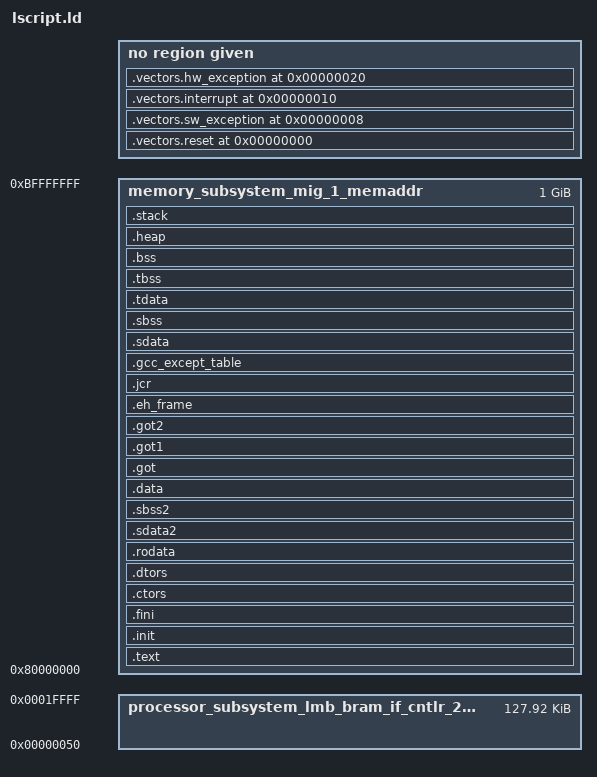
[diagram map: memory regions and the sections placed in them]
/*******************************************************************/
/*                                                                 */
/* This file is automatically generated by linker script generator.*/
/*                                                                 */
/* Version:                                 */
/*                                                                 */
/* Copyright (c) 2010-2016 Xilinx, Inc.  All rights reserved.      */
/*                                                                 */
/* Description : MicroBlaze Linker Script                          */
/*                                                                 */
/*******************************************************************/

_STACK_SIZE = DEFINED(_STACK_SIZE) ? _STACK_SIZE : 0x4000;
_HEAP_SIZE = DEFINED(_HEAP_SIZE) ? _HEAP_SIZE : 0x8000;

/* Define Memories in the system */

MEMORY
{
   processor_subsystem_lmb_bram_if_cntlr_2_Mem_processor_subsystem_lmb_bram_if_cntlr_1_Mem : ORIGIN = 0x50, LENGTH = 0x1FFB0
   memory_subsystem_mig_1_memaddr : ORIGIN = 0x80000000, LENGTH = 0x40000000
}

/* Specify the default entry point to the program */

ENTRY(_start)

/* Define the sections, and where they are mapped in memory */

SECTIONS
{
.vectors.reset 0x0 : {
   KEEP (*(.vectors.reset))
}

.vectors.sw_exception 0x8 : {
   KEEP (*(.vectors.sw_exception))
}

.vectors.interrupt 0x10 : {
   KEEP (*(.vectors.interrupt))
}

.vectors.hw_exception 0x20 : {
   KEEP (*(.vectors.hw_exception))
}

.text : {
   *(.text)
   *(.text.*)
   *(.gnu.linkonce.t.*)
} > memory_subsystem_mig_1_memaddr

.init : {
   KEEP (*(.init))
} > memory_subsystem_mig_1_memaddr

.fini : {
   KEEP (*(.fini))
} > memory_subsystem_mig_1_memaddr

.ctors : {
   __CTOR_LIST__ = .;
   ___CTORS_LIST___ = .;
   KEEP (*crtbegin.o(.ctors))
   KEEP (*(EXCLUDE_FILE(*crtend.o) .ctors))
   KEEP (*(SORT(.ctors.*)))
   KEEP (*(.ctors))
   __CTOR_END__ = .;
   ___CTORS_END___ = .;
} > memory_subsystem_mig_1_memaddr

.dtors : {
   __DTOR_LIST__ = .;
   ___DTORS_LIST___ = .;
   KEEP (*crtbegin.o(.dtors))
   KEEP (*(EXCLUDE_FILE(*crtend.o) .dtors))
   KEEP (*(SORT(.dtors.*)))
   KEEP (*(.dtors))
   PROVIDE(__DTOR_END__ = .);
   PROVIDE(___DTORS_END___ = .);
} > memory_subsystem_mig_1_memaddr

.rodata : {
   __rodata_start = .;
   *(.rodata)
   *(.rodata.*)
   *(.gnu.linkonce.r.*)
   __rodata_end = .;
} > memory_subsystem_mig_1_memaddr

.sdata2 : {
   . = ALIGN(8);
   __sdata2_start = .;
   *(.sdata2)
   *(.sdata2.*)
   *(.gnu.linkonce.s2.*)
   . = ALIGN(8);
   __sdata2_end = .;
} > memory_subsystem_mig_1_memaddr

.sbss2 : {
   __sbss2_start = .;
   *(.sbss2)
   *(.sbss2.*)
   *(.gnu.linkonce.sb2.*)
   __sbss2_end = .;
} > memory_subsystem_mig_1_memaddr

.data : {
   . = ALIGN(4);
   __data_start = .;
   *(.data)
   *(.data.*)
   *(.gnu.linkonce.d.*)
   __data_end = .;
} > memory_subsystem_mig_1_memaddr

.got : {
   *(.got)
} > memory_subsystem_mig_1_memaddr

.got1 : {
   *(.got1)
} > memory_subsystem_mig_1_memaddr

.got2 : {
   *(.got2)
} > memory_subsystem_mig_1_memaddr

.eh_frame : {
   *(.eh_frame)
} > memory_subsystem_mig_1_memaddr

.jcr : {
   *(.jcr)
} > memory_subsystem_mig_1_memaddr

.gcc_except_table : {
   *(.gcc_except_table)
} > memory_subsystem_mig_1_memaddr

.sdata : {
   . = ALIGN(8);
   __sdata_start = .;
   *(.sdata)
   *(.sdata.*)
   *(.gnu.linkonce.s.*)
   __sdata_end = .;
} > memory_subsystem_mig_1_memaddr

.sbss (NOLOAD) : {
   . = ALIGN(4);
   __sbss_start = .;
   *(.sbss)
   *(.sbss.*)
   *(.gnu.linkonce.sb.*)
   . = ALIGN(8);
   __sbss_end = .;
} > memory_subsystem_mig_1_memaddr

.tdata : {
   __tdata_start = .;
   *(.tdata)
   *(.tdata.*)
   *(.gnu.linkonce.td.*)
   __tdata_end = .;
} > memory_subsystem_mig_1_memaddr

.tbss : {
   __tbss_start = .;
   *(.tbss)
   *(.tbss.*)
   *(.gnu.linkonce.tb.*)
   __tbss_end = .;
} > memory_subsystem_mig_1_memaddr

.bss (NOLOAD) : {
   . = ALIGN(4);
   __bss_start = .;
   *(.bss)
   *(.bss.*)
   *(.gnu.linkonce.b.*)
   *(COMMON)
   . = ALIGN(4);
   __bss_end = .;
} > memory_subsystem_mig_1_memaddr

_SDA_BASE_ = __sdata_start + ((__sbss_end - __sdata_start) / 2 );

_SDA2_BASE_ = __sdata2_start + ((__sbss2_end - __sdata2_start) / 2 );

/* Generate Stack and Heap definitions */

.heap (NOLOAD) : {
   . = ALIGN(8);
   _heap = .;
   _heap_start = .;
   . += _HEAP_SIZE;
   _heap_end = .;
} > memory_subsystem_mig_1_memaddr

.stack (NOLOAD) : {
   _stack_end = .;
   . += _STACK_SIZE;
   . = ALIGN(8);
   _stack = .;
   __stack = _stack;
} > memory_subsystem_mig_1_memaddr

_end = .;
}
